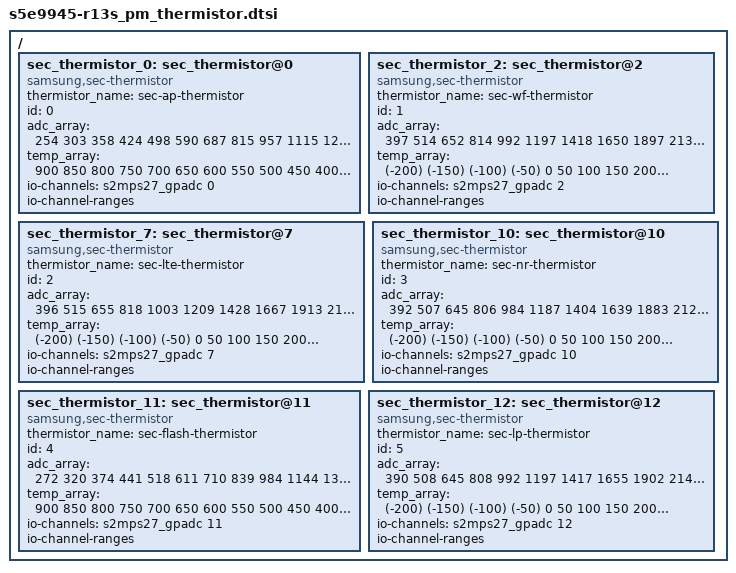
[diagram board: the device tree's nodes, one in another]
/*
 * SAMSUNG S5E9945 Power Management device tree source
 *
 * Copyright (c) 2024 Samsung Electronics Co., Ltd.
 *		http://www.samsung.com
 *
 * This program is free software; you can redistribute it and/or modify
 * it under the terms of the GNU General Public License version 2 as
 * published by the Free Software Foundation.
 */

/ {
	fragment@model {
		target-path = "/";
		__overlay__ {
			sec_thermistor_0: sec_thermistor@0 {
				compatible = "samsung,sec-thermistor";
				status = "okay";
				thermistor_name = "sec-ap-thermistor";
				id = <0>;

				adc_array = <254 303 358 424 498 590 687 815 957 1115
					1288 1486 1699 1923 2156 2401 2637 2859 3062 3242
					3406 3540 3661>;

				temp_array = <900 850 800 750 700 650 600 550 500 450
					  400 350 300 250 200 150 100 50 0 (-50)
					  (-100) (-150) (-200)>;

				io-channels = <&s2mps27_gpadc 0>;
				io-channel-names = "adc-ap-temp";
				io-channel-ranges;
			};

			sec_thermistor_2: sec_thermistor@2 {
				compatible = "samsung,sec-thermistor";
				status = "okay";
				thermistor_name = "sec-wf-thermistor";
				id = <1>;

				adc_array = <397 514 652 814 992 1197 1418 1650 1897 2133
					2359 2574 2774 2953 3117 3261 3391 3489 3584 3658
					3727 3782 3831>;

				temp_array = <(-200) (-150) (-100) (-50) 0 50 100 150 200 250
					300 350 400 450 500 550 600 650 700 750
					800 850 900>;

				io-channels = <&s2mps27_gpadc 2>;
				io-channel-names = "adc-wf-temp";
				io-channel-ranges;
			};


			sec_thermistor_7: sec_thermistor@7 {
				compatible = "samsung,sec-thermistor";
				status = "okay";
				thermistor_name = "sec-lte-thermistor";
				id = <2>;

				adc_array = <396 515 655 818 1003 1209 1428 1667 1913 2155
					2381 2597 2797 2972 3130 3275 3402 3499 3592 3665
					3732 3786 3834>;

				temp_array = <(-200) (-150) (-100) (-50) 0 50 100 150 200 250
					300 350 400 450 500 550 600 650 700 750
					800 850 900>;

				io-channels = <&s2mps27_gpadc 7>;
				io-channel-names = "adc-lte-temp";
				io-channel-ranges;
			};

			sec_thermistor_10: sec_thermistor@10 {
				compatible = "samsung,sec-thermistor";
				status = "okay";
				thermistor_name = "sec-nr-thermistor";
				id = <3>;

				adc_array = <392 507 645 806 984 1187 1404 1639 1883 2120
					2348 2563 2763 2942 3103 3249 3379 3479 3573 3651
					3718 3774 3823>;

				temp_array = <(-200) (-150) (-100) (-50) 0 50 100 150 200 250
					300 350 400 450 500 550 600 650 700 750
					800 850 900>;

				io-channels = <&s2mps27_gpadc 10>;
				io-channel-names = "adc-nr-temp";
				io-channel-ranges;
			};

			sec_thermistor_11: sec_thermistor@11 {
				compatible = "samsung,sec-thermistor";
				status = "okay";
				thermistor_name = "sec-flash-thermistor";
				id = <4>;

				adc_array = <272 320 374 441 518 611 710 839 984 1144
					1319 1515 1731 1958 2193 2435 2669 2889 3091 3269
					3429 3560 3677>;

				temp_array = <900 850 800 750 700 650 600 550 500 450
					  400 350 300 250 200 150 100 50 0 (-50)
					  (-100) (-150) (-200)>;

				io-channels = <&s2mps27_gpadc 11>;
				io-channel-names = "adc-flash-temp";
				io-channel-ranges;
			};

			sec_thermistor_12: sec_thermistor@12 {
				compatible = "samsung,sec-thermistor";
				status = "okay";
				thermistor_name = "sec-lp-thermistor";
				id = <5>;

				adc_array = <390 508 645 808 992 1197 1417 1655 1902 2142
					2371 2588 2788 2964 3122 3268 3396 3494 3586 3661
					3728 3783 3832>;

				temp_array = <(-200) (-150) (-100) (-50) 0 50 100 150 200 250
					300 350 400 450 500 550 600 650 700 750
					800 850 900>;

				io-channels = <&s2mps27_gpadc 12>;
				io-channel-names = "adc-lp-temp";
				io-channel-ranges;
			};
		}; /* end of __overlay__ */
	}; /* end of fragment */
}; /* end of root */
